# M55M1 register map
File version: 1.0
Registers are 32-bit, read-write, reset 0x0 unless marked. A register's access mark holds for its fields unless they carry their own. Offsets are from the block's base; [hi:lo] are bit positions; {n}, {i} and the like mark numbered series; 'fields as' and 'values as' point back to an identical list.

## SPIM0 — SPIM Register Map
Base 0x40042000
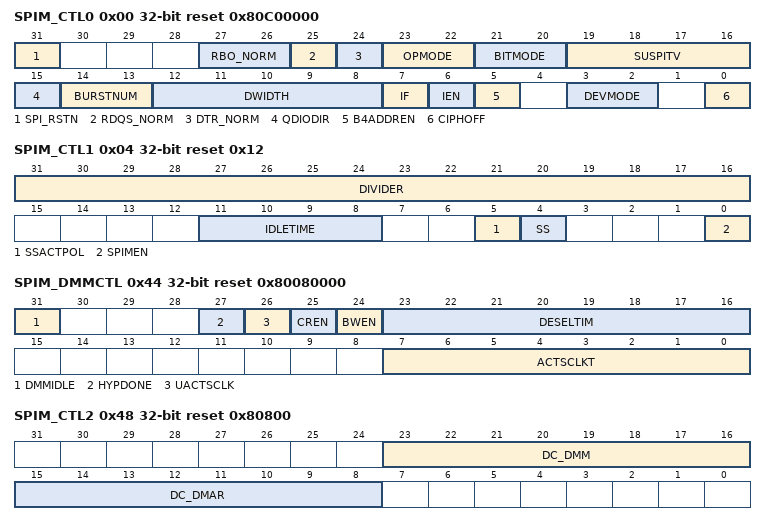
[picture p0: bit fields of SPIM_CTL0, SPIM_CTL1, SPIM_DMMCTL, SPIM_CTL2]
0x00 SPIM_CTL0 reset 0x80C00000 — Control and Status Register 0
  [31] SPI_RSTN — SPI Flash Reset Enable Bit for SPI Flash
    0=Set SPIM_RESETn pin to low; 1=Set SPIM_RESETn to high (Default)
  [27:26] RBO_NORM — Received Data Byte Order of Normal I/O Mode for Octal SPI Flash
    0=Byte order of received data from SPI Flash is byte0. Byte order of received data from SPI Flash is byte0, byte1. Byte order of received data from SPI Flash is byte0, byte1, byte2. Byte order of received data from SPI Flash is byte0, byte1, byte2, byte3; 1=Byte order of received data from SPI Flash is byte1, byte0. Byte order of received data from SPI Flash is byte2, byte1, byte0. Byte order of received data from SPI Flash is byte3, byte2, byte1, byte0; 2=Byte order of received data from SPI Flash is byte1, byte0, byte3, byte2; 3=Byte order of received data from SPI Flash is byte2, byte3, byte0, byte1
  [25] RDQS_NORM — Read DQS Mode Enable Bit for Normal I/O Mode. In SPI master mode, SPI uses read DQS signal, which is generated by SPI Flash, to sample RX data from SPI Flash when Read DQS mode is enabled. Note: Only used for normal I/O mode.
    0=Read DQS mode Disabled; 1=Read DQS mode Enabled
  [24] DTR_NORM — Double Transfer Rate Mode Enable Bit for Normal I/O Mode. In master mode, SPI will receive data at both rising edge and falling edge of SPI bus clock. Note: Only used for normal I/O mode.
    0=DTR mode Disabled (i.e. Single Transfer Rate (STR) mode enabled); 1=DTR mode Enabled
  [23:22] OPMODE — SPI Function Operation Mode. Note 1: In DMA write mode, hardware will send just one page program command per operation. Users must take care of cross-page cases. Note 2: For SPI Flash and Hyper device with 32 Mbytes, access address range is from 0x00000000 to 0x01FFFFFF when using Normal I/O mode, DMA write mode, and DMA read mode to write/read SPI Flash and Hyper device. Please user check size of used SPI Flash component to know access address range of SPI Flash and Hyper device. Note 3: For SPI Flash and Hyper device with 32 Mbytes, access address range is from 0x08000000 to 0x09FFFFFF when using Direct Memory mapping mode (DMM mode) to read SPI Flash and write/read Hyper device. Please user check size of used storage components to know access address range.
    0=Normal I/O mode; 1=DMA write mode; 2=DMA read mode; 3=Direct Memory Mapping mode (DMM mode) (Default)
  [21:20] BITMODE — SPI Interface Bit Mode. Note: Only used for normal I/O mode.
    0=Standard mode; 1=Dual mode; 2=Quad mode; 3=Octal mode
  [19:16] SUSPITV — Suspend Interval. Note: Only used for normal I/O mode.
    0=Hardware will control this item by DIVIDER (SPIM_CTL1[31:16]) automatically; 1=8 AHB clock cycles; 14=21 AHB clock cycles; 15=22 AHB clock cycles
  [15] QDIODIR — SPI Interface Direction Select for Normal I/O Mode. Note: Only used for normal I/O mode.
    0=Interface signals are input; 1=Interface signals are output
  [14:13] BURSTNUM — Transmit/Receive Burst Number. This field specifies how many transmit/receive transactions should be executed continuously in one transfer. Note: Only used for normal I/O Mode.
    0=Only one transmit/receive transaction will be executed in one transfer; 1=Two successive transmit/receive transactions will be executed in one transfer; 2=Three successive transmit/receive transactions will be executed in one transfer; 3=Four successive transmit/receive transactions will be executed in one transfer
  [12:8] DWIDTH — Transmit/Receive Bit Length. This specifies how many bits are transmitted/received in one transmit/receive transaction. Note 1: Only used for normal I/O mode. Note 2: Only 8, 16, 24, and 32 bits are allowed. Other bit length will result in incorrect transfer. Note 3: Only 16 and 32 bits are allowed when both of Octal mode and DTR mode of normal I/O mode are enabled. Other bit length will result in incorrect transfer.
    7=8 bits; 15=16 bits; 23=24 bits; 31=32 bits
  [7] IF — Interrupt Flag. Write Operation:
    0=No effect. The transfer has not finished yet; 1=Write 1 to clear. The transfer has done
  [6] IEN — Interrupt Enable Bit
    0=SPIM Interrupt Disabled; 1=SPIM Interrupt Enabled
  [5] B4ADDREN — 4-byte Address Mode Enable Bit. Note: Used for DMA write mode, DMA read mode, and DMM mode.
    0=3-byte address mode Enabled; 1=4-byte address mode Enabled
  [3:2] DEVMODE — Device Mode
    0=SPIROM operates in SPI Flash device mode; 1=SPIROM operates in HYPER RAM device mode; 2=SPIROM operates in HYPER Flash device mode
  [0] CIPHOFF — Cipher Disable Bit
    0=Cipher function Enabled; 1=Cipher function Disabled
0x04 SPIM_CTL1 reset 0x12 — Control and Status Register 1
  [31:16] DIVIDER — Clock Divider Register. The value in this field is the frequency divider of the AHB clock (HCLK) to generate the serial SPI output clock 'SCLK' on the output SPIM_CLK pin. The desired frequency is obtained according to the following equation: . Note 1: When set DIVIDER to zero, the frequency of SPIM_CLK will be equal to the frequency of HCLK. Note 2: SCLK is serial SPI output clock. Note 3: Each SPI Flash command has the limitation of the maximum operation frequency of SCLK. Please check the specification of the used SPI Flash component to decide the frequency of SPI Flash clock for different command operations of SPI Flash. Note 4: For DTR (Double Transfer Rate) commands, the setting values of DIVIDER are only 1,2,4,8,16,32,.... Note 5: For commands of HyperBus device, the setting values of DIVIDER are only 1 and 2.
  [11:8] IDLETIME — Idle Time Interval. In DMM mode, IDLETIME is set to control the minimum idle time between two SPI Flash accesses.
  [5] SSACTPOL — Slave Select Active Level. It defines the active level of device/slave select signal (SPIM_SS), as shown in Table 6.341
    0=The SPIM_SS slave select signal is active low; 1=The SPIM_SS slave select signal is active high
  [4] SS — Slave Select Active Enable Bit. Note: This interface can only drive one device/slave at a given time. Therefore, the slave selects of the selected device must be set to its active level before starting any read or write transfer. Functional description of SSACTPOL(SPIM_CTL1[5]) and SS is shown in Table 6.341
    0=SPIM_SS is in active level; 1=SPIM_SS is in inactive level (Default)
  [0] SPIMEN — Go and Busy Status. Write Operation: Note: All registers should be set before writing 1 to the SPIMEN bit. When a transfer is in progress, user should not write to any register of this peripheral.
    0=No effect. The transfer has done; 1=Start the transfer. This bit remains set during the transfer and is automatically cleared after transfer finished. The transfer has not finished yet
0x0C SPIM_RXCLKDLY — RX Clock Delay Control Register
  [3:0] RDDLYSEL — Sampling Clock Delay Selection for Received Data for Normal I/O Mode, DMA Read Mode, DMA Write Mode, Direct Memory Mapping Mode, and SPI FLASH Only. Determine the number of inserted delay cycles. Used to adjust the sampling clock of received data to latch the correct data. 0x0: No delay. (Default). 0x1: Delay 0.5 SPI Flash clock. 0x2: Delay 1 SPI Flash clocks. 0x3: Delay 1.5 SPI Flash clocks. ... 0xf: Delay 7.5 SPI Flash clocks. Note 1: The manufacturer or device ID of SPI Flash component can be used to determine the correct setting value of RDDLYSEL. An example is given as follows. For example, the manufacturer ID and device ID of SPI Flash for some vendor are 0xEF and 0x1234 separately. First, set RDDLYSEL to 0x0, and use read manufacturer id/device id command to read the manufacturer id of SPI Flash by using normal I/O mode (the manufacturer id is 0xEF (1110_1111) in this example). If the manufacturer ID which reads from SPI Flash is 0xF7 (1111_0111), it denotes that manufacturer id is shifted the right by 1 bit and most significant bit (MSB) of manufacturer id is assigned to 1. According to manufacturer id reads from SPI Flash, RDDLYSEL needs to be set to 0x1 to receive SPI Flash data correctly. Note 2: If read command of SPI FLASH sneds out DS (Data Strobe), and we recommand to use DS and HYPERDLL to sample RX data from SPI FLASH. RDDLYSEL is only used to sample RX data when read command of SPI FLASH doesn't send out DS (Data Strobe).
{0x10+4i} SPIM_RX{i} ro (i=0..3) — Data Receive Register {i}
  [31:0] RXDAT — Data Receive Register. The Data Receive Registers hold the received data of the last executed transfer. Number of valid RX registers is specified in SPIM_CTL0[BURSTNUM]. If BURSTNUM 0, received data are held in the most significant RXDAT register first. Number of valid-bit is specified in SPIM_CTL0[DWIDTH]. If DWIDTH is 16, 24, or 32, received data are held in the least significant byte of RXDAT register first. In a byte, received data are held in the most significant bit of RXDAT register first.
{0x20+4i} SPIM_TX{i} (i=0..3) — Data Transmit Register {i}
  [31:0] TXDAT — Data Transmit Register. The Data Transmit Registers hold the data to be transmitted in next transfer. Number of valid TXDAT registers is specified in SPIM_CTL0[BURSTNUM]. If BURSTNUM 0, data are transmitted in the most significant TXDAT register first. Number of valid-bit is specified in SPIM_CTL0[DWIDTH]. If DWIDTH is 16, 24, or 32, data are transmitted in the least significant byte of TXDAT register first. In a byte, data are transmitted in the most significant bit of TXDAT register first.
0x30 SPIM_SRAMADDR — SRAM Memory Address Register
  [31:0] ADDR — SRAM Memory Address. For DMA Read mode, this is the destination address for DMA transfer. For DMA Write mode, this is the source address for DMA transfer. Note: This address must be 8bytes aligned.
0x34 SPIM_DMACNT — DMA Transfer Byte Count Register
  [23:0] DMACNT — DMA Transfer Byte Count Register. It indicates the transfer length for DMA process. Note 1: The unit for counting is byte and the number must be the multiple of 8. Note 2: The page program instruction allows from one byte to 256 bytes (a page) of data to be programmed at previously erased (FFh) memory locations for SPI Flash device. Note 3: A maximum of 512 bytes can be programmed as long as an aligned 512-byte address boundary is not crossed for HYPER Flash device. Note 4: Please check specification of used SPI Flash and Hyper Flash to know maximum byte length of page program and program address boundary.
0x38 SPIM_FADDR — Address Register for SPI Flash and Hyper Device
  [31:0] ADDR — Address Register for SPI Flash and Hyper Device. For DMA Read mode, this is the source address for DMA transfer. For DMA Write mode, this is the destination address for DMA transfer. Note 1: This address must be 8bytes aligned. Note 2: A maximum of 512 bytes can be programmed as long as an aligned 512-byte address boundary is not crossed for HYPER Flash device. Note 3: For SPI Flash and Hyper device with 32 Mbytes, the value 'ADDR' is from 0x00000000 to 0x00FFFFFF when using DMA write mode and DMA read mode to write/read data of SPI Flash and Hyper device. Please check specification of used SPI Flash and Hyper Flash to know access address range and program address boundary.
0x44 SPIM_DMMCTL reset 0x80080000 — Direct Memory Mapping Mode Control Register
  [31] DMMIDLE — DMM Mode Idle State for DMM mode only. Note 1: User can polling this status register to know DMM mode is in idle state or busy state when user wants to change OPMODE (SPIM_CTL0[23:22]) from DMM mode to Normal I/O mode/DMA write mode/DMA read mode, SPIM cipher enable/disable switch (SPIM_CTL[0]). Note 2: This status register keep to 1 when SPIM is in Normal I/O mode, DMA write mode, and DMA read mode.
    0=DMM mode is in busy state; 1=DMM mode is in idle state
  [27] HYPDONE — Set All Read/Write Operations Done in Direct Memory Mapping Mode for HYPER Device. Note 1: User must set this bit to 1 after all read/write operations are done in DMM mode for HYPER device, and wait this bit to 0 to indicate that finish process of all read/write operations is done in DMM mode for HYPER device. Note 2: User must set this bit to 1 before user switches SPIM operation mode (SPIM_CTL0[23:22]) from DMM mode to Normal I/O mode, DMA write mode, or DMA read mode.
    0=Finish process of all read/write operations is done in DMM mode for HYPER device; 1=Finish process of all read/write operations is executed in DMM mode for HYPER device. This bit is cleared by hardware automatically
  [26] UACTSCLK — User Sets SPI Flash Active SCLK Time for Direct Memory Mapping Mode, DMA Write Mode, and DMA Read Mode Only. Note: When user wants to set ACTSCLKT(SPIM_DMMCTL[7:0]) manually, please set UACTSCLK to 1.
    0=According to DIVIDER(SPIM_CTL1[31:16]), ACTSCLKT(SPIM_DMMCTL[7:0]) is set by hardware automatically. (Default); 1=Set ACTSCLKT(SPIM_DMMCTL[7:0]) by user manually
  [25] CREN — Continuous Read Mode Enable Bit for Direct Memory Mapping Mode, Read Command Codes 0xBB, 0xEB, 0xE7, 0x0D, 0xBD, and 0xED Only. For read operations of SPI Flash, commands of fast read quad I/O (0xEB), word read quad I/O (0xE7), fast read dual I/O (0xBB), DTR fast read (0x0D), DTR fast read dual I/O (0xBD), and DTR fast read quad I/O (0xED) can further reduce cycles of command phase overhead through setting the 'continuous read mode' after address phase. Note: When user sets CREN to 1 to use continuous read mode, SPIM_MODE must be set by used SPI Flash specifications.
    0=Continuous Read Mode Disabled. (Default); 1=Continuous Read Mode Enabled
  [24] BWEN — 16 Bytes Burst Wrap Mode Enable Bit for Direct Memory Mapping Mode, and Read Command Code 0xEB, and 0xE7 Only
    0=Burst Wrap Mode Disabled. (Default); 1=Burst Wrap Mode Enabled
  [23:16] DESELTIM — SPI Flash Deselect Time for Direct Memory Mapping Mode Only. Set the minimum time width of SPI Flash deselect time (i.e. Minimum SPIM_SS deselect time), as shown in Figure 6.345. Note 3: Please check the used SPI Flash specification to know the setting value of this register, and different SPI Flash vendor may use different setting values.
  [7:0] ACTSCLKT — SPI Flash Active SCLK Time for Direct Memory Mapping Mode, DMA Write Mode, and DMA Read Mode Only. The bits set time interval between SPIM SS active edge and the position edge of the first serial SPI output clock, as shown in Figure 6.345. Note 2: SCLK is SPI output clock. Note 3: Please check the used SPI Flash specification to know the setting value of this register, and different SPI Flash vendor may use different setting values.
0x48 SPIM_CTL2 reset 0x80800 — Control and Status Register 2
  [23:16] DC_DMM — Dummy Cycle Number for Direct Memory Mapping Mode Only. Set number of dummy cycles for direct memory mapping mode only. Note 1: When there is not any dummy cycles in this used read command of SPI Flash, user must set DC_DMM to 0x0. Note 2: Number of dummy cycles depends on the frequency of SPI output clock, SPI Flash vendor, and read command types. Please check the used SPI Flash specification to know the setting value of this number of dummy cycles.
  [15:8] DC_DMAR — Dummy Cycle Number for DMA Read Mode Only. Set number of dummy cycles for DMA read mode only. Note 1: When there is not any dummy cycles in this used read command of SPI Flash, user must set DC_DMAR to 0x0. Note 2: Number of dummy cycles depends on the frequency of SPI output clock, SPI Flash vendor, and read command types. Please check the used SPI Flash specification to know the setting value of this number of dummy cycles.
0x4C SPIM_CMDCODE — Command Code Register
  [31:0] CMDCODE — SPI Flash Command Code. The SPI Flash command codes are separated in the following types. Page Program Command Code for DMA Write mode of SPIM. Read Command Code for DMA Read mode and DMM mode of SPIM. Note 1: Quad mode of SPI Flash must be enabled first by normal I/O mode before using quad page program/quad read commands. Note 2: Please check SPI Flash specifications for support command codes. Note 3: Please disable 'continuous read mode' and 'burst wrap mode' before DMA write mode of SPI Flash controller is used to program data of SPI Flash.
0x50 SPIM_MODE — Mode Data Register
  [31:0] MODEDATA — Mode Data Register. Set output data for mode phase. When user sets this mode data (Note1) and set CREN(SPIM_DMMCTL[25]) to enter continuous read mode, this will reduce the command phase by eight clocks and allows the read address to be immediately entered after SPIM_SS asserted to active. (Note1). Note 1: Please check the used SPI Flash specification to know the setting value of this mode bits data, and different SPI Flash vendor may use different setting values.
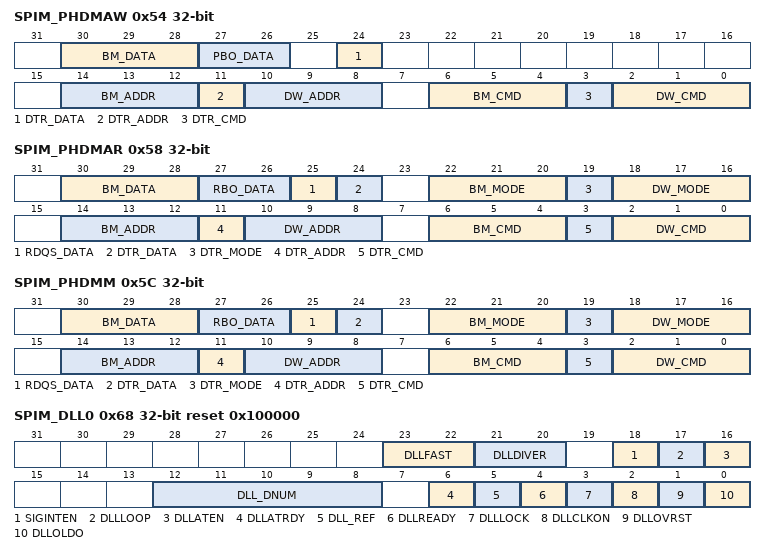
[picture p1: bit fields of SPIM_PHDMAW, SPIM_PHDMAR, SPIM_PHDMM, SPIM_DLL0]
0x54 SPIM_PHDMAW — Phase Setting Register for DMA Write Mode
  [30:28] BM_DATA — SPI Interface Bit Mode for Data Phase. Note: Only used for DMA Write mode.
    0=Standard mode; 1=Dual mode; 2=Quad mode; 3=Octal mode
  [27:26] PBO_DATA — Program Data Byte Order of Program Data Phase for Octal SPI Flash. Note: Only used for DMA Write mode.
    0=Byte order of program data to SPI Flash is byte0, byte1, byte2, byte3, byte4, byte5, byte6, byte7; 1=Byte order of program data to SPI Flash is byte7, byte6, byte5, byte4, byte3, byte2, byte1, byte0; 2=Byte order of program data to SPI Flash is byte1, byte0, byte3, byte2, byte5, byte4, byte7, byte6; 3=Byte order of program data to SPI Flash is byte6, byte7, byte4, byte5, byte2, byte3, byte0, byte1
  [24] DTR_DATA — Double Transfer Rate Mode Enable Bit for Data Phase. In master mode, SPI will receive data at both rising edge and falling edge of SPI bus clock. Note: Only used for DMA Write mode.
    values as SPIM_CTL0.DTR_NORM
  [14:12] BM_ADDR — SPI Interface Bit Mode for Address Phase. Note: Only used for DMA Write mode.
    0=Standard mode; 1=Dual mode; 2=Quad mode; 3=Octal mode
  [11] DTR_ADDR — Double Transfer Rate Mode Enable Bit for Address Phase. In master mode, SPI will transmit data at both rising edge and falling edge of SPI bus clock. Note: Only used for DMA Write mode.
    values as SPIM_CTL0.DTR_NORM
  [10:8] DW_ADDR — Data Width for Address Phase. This specifies how many bits are transmitted in this phase. Note: Only used for DMA Write mode.
    0=No address phase; 1=8 bits; 2=16 bits; 3=24 bits; 4=32 bits
  [6:4] BM_CMD — SPI Interface Bit Mode for Command Phase. Note: Only used for DMA Write mode.
    0=Standard mode; 1=Dual mode; 2=Quad mode; 3=Octal mode
  [3] DTR_CMD — Double Transfer Rate Mode Enable Bit for Command Phase. In master mode, SPI will transmit data at both rising edge and falling edge of SPI bus clock. Note: Only used for DMA Write mode.
    values as SPIM_CTL0.DTR_NORM
  [2:0] DW_CMD — Data Width for Command Phase. This specifies how many bits are transmitted in this phase. Note: Only used for DMA Write mode.
    0=No command phase; 1=8 bits; 2=16 bits; 3=24 bits; 4=32 bits
0x58 SPIM_PHDMAR — Phase Setting Register for DMA Read Mode
  [30:28] BM_DATA — SPI Interface Bit Mode for Data Phase. Note: Only used for DMA Read mode.
    0=Standard mode; 1=Dual mode; 2=Quad mode; 3=Octal mode
  [27:26] RBO_DATA — Received Data Byte Order of Received Data Phase for Octal SPI Flash. Note: Only used for DMA Read mode.
    0=Byte order of received data to SPI Flash is byte0, byte1, byte2, byte3, byte4, byte5, byte6, byte7; 1=Byte order of received data to SPI Flash is byte7, byte6, byte5, byte4, byte3, byte2, byte1, byte0; 2=Byte order of received data to SPI Flash is byte1, byte0, byte3, byte2, byte5, byte4, byte7, byte6; 3=Byte order of received data to SPI Flash is byte6, byte7, byte4, byte5, byte2, byte3, byte0, byte1
  [25] RDQS_DATA — Read DQS Mode Enable Bit for Data Phase. In SPI master mode, SPI uses read DQS signal, which is generated by SPI Flash, to sample RX data from SPI Flash when Read DQS mode is enabled. Note: Only used for DMA Read mode.
    0=Read DQS mode Disabled; 1=Read DQS mode Enabled
  [24] DTR_DATA — Double Transfer Rate Mode Enable Bit for Data Phase. In master mode, SPI will receive data at both rising edge and falling edge of SPI bus clock. Note: Only used for DMA Read mode.
    values as SPIM_CTL0.DTR_NORM
  [22:20] BM_MODE — SPI Interface Bit Mode for Mode Phase. Note: Only used for DMA Read mode.
    0=Standard mode; 1=Dual mode; 2=Quad mode; 3=Octal mode
  [19] DTR_MODE — Double Transfer Rate Mode Enable Bit for Mode Phase. In master mode, SPI will transmit data at both rising edge and falling edge of SPI bus clock. Note: Only used for DMA Read mode.
    values as SPIM_CTL0.DTR_NORM
  [18:16] DW_MODE — Data Width for Mode Phase. This specifies how many bits are transmitted in this phase. Note: Only used for DMA Read mode.
    0=No mode phase; 1=8 bits; 2=16 bits; 3=24 bits; 4=32 bits
  [14:12] BM_ADDR — SPI Interface Bit Mode for Address Phase. Note: Only used for DMA Read mode.
    0=Standard mode; 1=Dual mode; 2=Quad mode; 3=Octal mode
  [11] DTR_ADDR — Double Transfer Rate Mode Enable Bit for Address Phase. In master mode, SPI will transmit data at both rising edge and falling edge of SPI bus clock. Note: Only used for DMA Read mode.
    values as SPIM_CTL0.DTR_NORM
  [10:8] DW_ADDR — Data Width for Address Phase. This specifies how many bits are transmitted in this phase. Note: Only used for DMA Read mode.
    values as SPIM_PHDMAW.DW_ADDR
  [6:4] BM_CMD — SPI Interface Bit Mode for Command Phase. Note: Only used for DMA Read mode.
    0=Standard mode; 1=Dual mode; 2=Quad mode; 3=Octal mode
  [3] DTR_CMD — Double Transfer Rate Mode Enable Bit for Command Phase. In master mode, SPI will transmit data at both rising edge and falling edge of SPI bus clock. Note: Only used for DMA Read mode.
    values as SPIM_CTL0.DTR_NORM
  [2:0] DW_CMD — Data Width for Command Phase. This specifies how many bits are transmitted in this phase. Note: Only used for DMA Read mode.
    values as SPIM_PHDMAW.DW_CMD
0x5C SPIM_PHDMM — Phase Setting Register for Direct Memory Mapping Mode
  [30:28] BM_DATA — SPI Interface Bit Mode for Data Phase. Note: Only used for Direct Memory Mapping mode.
    0=Standard mode; 1=Dual mode; 2=Quad mode; 3=Octal mode
  [27:26] RBO_DATA — Received Data Byte Order of Received Data Phase for Octal SPI Flash. Note: Only used for Direct Memory Mapping mode.
    values as SPIM_PHDMAR.RBO_DATA
  [25] RDQS_DATA — Read DQS Mode Enable Bit for Data Phase. In SPI master mode, SPI uses read DQS signal, which is generated by SPI Flash, to sample RX data from SPI Flash when Read DQS mode is enabled. Note: Only used for Direct Memory Mapping mode.
    0=Read DQS mode Disabled; 1=Read DQS mode Enabled
  [24] DTR_DATA — Double Transfer Rate Mode Enable Bit for Data Phase. In master mode, SPI will receive data at both rising edge and falling edge of SPI bus clock. Note: Only used for Direct Memory Mapping mode.
    values as SPIM_CTL0.DTR_NORM
  [22:20] BM_MODE — SPI Interface Bit Mode for Mode Phase. Note: Only used for Direct Memory Mapping mode.
    0=Standard mode; 1=Dual mode; 2=Quad mode; 3=Octal mode
  [19] DTR_MODE — Double Transfer Rate Mode Enable Bit for Mode Phase. In master mode, SPI will transmit data at both rising edge and falling edge of SPI bus clock. Note: Only used for Direct Memory Mapping mode.
    values as SPIM_CTL0.DTR_NORM
  [18:16] DW_MODE — Data Width for Mode Phase. This specifies how many bits are transmitted in this phase. Note: Only used for Direct Memory Mapping mode.
    0=No mode phase; 1=8 bits; 2=16 bits; 3=24 bits; 4=32 bits
  [14:12] BM_ADDR — SPI Interface Bit Mode for Address Phase. Note: Only used for Direct Memory Mapping mode.
    0=Standard mode; 1=Dual mode; 2=Quad mode; 3=Octal mode
  [11] DTR_ADDR — Double Transfer Rate Mode Enable Bit for Address Phase. In master mode, SPI will transmit data at both rising edge and falling edge of SPI bus clock. Note: Only used for Direct Memory Mapping mode.
    values as SPIM_CTL0.DTR_NORM
  [10:8] DW_ADDR — Data Width for Address Phase. This specifies how many bits are transmitted in this phase. Note: Only used for Direct Memory Mapping mode.
    values as SPIM_PHDMAW.DW_ADDR
  [6:4] BM_CMD — SPI Interface Bit Mode for Command Phase. Note: Only used for Direct Memory Mapping mode.
    0=Standard mode; 1=Dual mode; 2=Quad mode; 3=Octal mode
  [3] DTR_CMD — Double Transfer Rate Mode Enable Bit for Command Phase. In master mode, SPI will transmit data at both rising edge and falling edge of SPI bus clock. Note: Only used for Direct Memory Mapping mode.
    values as SPIM_CTL0.DTR_NORM
  [2:0] DW_CMD — Data Width for Command Phase. This specifies how many bits are transmitted in this phase. Note: Only used for Direct Memory Mapping mode.
    values as SPIM_PHDMAW.DW_CMD
0x68 SPIM_DLL0 reset 0x100000 — HYPERDLL Control and Status Register 0
  [23:22] DLLFAST — Band Selection of HYPERDLL Reference Clock
    0=When frequency of HYPERDLL reference clock equals to 100 MHz; 1=When frequency of HYPERDLL reference clock is greater than 100 MHz
  [21:20] DLLDIVER — Divider Number Selection of HYPERDLL Internal Clock Divder
    0=Output frequency of HYPERDLL internal clock divdier equals to input frequency of HYPERDLL internal clock divdier; 1=Output frequency of HYPERDLL internal clock divdier is (input frequency of HYPERDLL internal clock divdier)/2; 2=Output frequency of HYPERDLL internal clock divdier is (input frequency of HYPERDLL internal clock divdier)/4; 3=Output frequency of HYPERDLL internal clock divdier is (input frequency of HYPERDLL internal clock divdier)/8
  [18] SIGINTEN — Selection for Clock Source DQS/RWDS of HYPERDLL Open Loop Delay Line
    0=HYPERDLL clock source DQS/RWDS of HYPERDLL open loop delay line is from SPI Flash and HYPER device; 1=HYPERDLL clock source DQS/RWDS of HYPERDLL open loop delay line is from HYPERDLL internal clock divider
  [17] DLLLOOP — HYPERDLL Delay Time Self-Test Enable Bit
    0=HYPERDLL Delay time self-test is disabled; 1=HYPERDLL Delay time self-test is enabled
  [16] DLLATEN — HYPERDLL Auto Trim Enable Bit
    0=HYPERDLL auto trim function is disabled for HYPERDLL normal mode and HYPERDLL BIST1 mode; 1=HYPERDLL auto trim function is enabled for HYPERDLL normal mode and HYPERDLL BIST1 mode
  [12:8] DLL_DNUM — HYPERDLL Delay Step Number. Set HYPERDLL delay step number. 0x0: No delay. (Default). 0x1: HYPERDLL delay read data strobe of RWDS and DQS with 1x (SPIM output bus clock period)/32. 0x2: HYPERDLL delay read data strobe of RWDS and DQS with 2x (SPIM output bus clock period)/32. 0x3: HYPERDLL delay read data strobe of RWDS and DQS with 3x (SPIM output bus clock period)/32 ... 0x1f: HYPERDLL delay read data strobe of RWDS and DQS with 31x (SPIM output bus clock period)/32
  [6] DLLATRDY ro — HYPERDLL Auto Trim Ready Status Bit (Read Only). Note 1: User needs to check status of HYPERDLL auto trim function before HYPERDLL output can be used for flow of HYPERDLL auto trim correctly. Note 2: This status bit is valid only when DLLATEN (SPIM_DLL0[16]) is enabled. Note 3: This status bit will be cleared to 0 when DLLATEN (SPIM_DLL0[16]) is disabled.
    0=HYPERDLL auto trim function is not in ready state when DLLATEN (SPIM_DLL0[16]) is enabled and HYPERDLL output is ready; 1=HYPERDLL auto trim function is in ready state when DLLATEN (SPIM_DLL0[16]) is enabled and HYPERDLL output is ready
  [5] DLL_REF ro — HYPERDLL Refresh Status Bit (Read Only). Note 1: This bit will be cleared automatically. Note 2: User needs to check this bit to know that the refresh flow of HYPERDLL circuit is finished or not.
    0=The updating flow of new HYPERDLL delay step number DLL_DNUM (SPIM_DLL0[13:8]) of HYPERDLL circuit is finished; 1=HYPERDLL circuit is updating the new HYPERDLL delay step number DLL_DNUM (SPIM_DLL0[13:8])
  [4] DLLREADY ro — HYPERDLL Output Ready Status Bit (Read Only). Note: User needs to check status of HYPERDLL output to ready before HYPERDLL output can be used correctly.
    0=HYPERDLL output is not ready, and HYPERDLL output is not ready to use; 1=HYPERDLL output is ready, and HYPERDLL output is ready to use
  [3] DLLLOCK ro — HYPERDLL Lock Status Bit (Read Only). Note: User needs to check HYPERDLL Datasheet to know HYPERDLL lock time.
    0=HYPERDLL is not locked after HYPERDLL reference clock sends to HYPERDLL circuit; 1=HYPERDLL is locked after HYPERDLL reference clock sends to HYPERDLL circuit
  [2] DLLCLKON ro — HYPERDLL Clock Divider Circuit Status Bit (Read Only). Note: User needs to check HYPERDLL Datasheet to know time interval that HYPERDLL clock divider circuit can be enabled after HYPERDLL OLDO is enabled.
    0=HYPERDLL clock divider circuit is disabled after HYPERDLL OLDO is enabled; 1=HYPERDLL clock divider circuit is enabled after HYPERDLL OLDO is enabled
  [1] DLLOVRST — HYPERDLL Output Valid Counter Reset Enable. Note 1: This bit will be cleared automatically. Note 2: User only writes 1'b1 to DLLOVRST once before user starts to trim delay step number of HYPERDLL. User needs to set DLLOVRST again to wait HYPERDLL output valid when one of frequencies of SPI output bus clock/HyperBus clock, HYPERDLL reference clock, or RWDS/DS clock are changed.
    0=HYPERDLL output valid counter is not reseted to 0x0 and it does not start to count; 1=HYPERDLL output valid counter is reseted to 0x0 and it starts to count from 0x0 to DLLOVNUM (SPIM_DLL1[15:0])
  [0] DLLOLDO — HYPERDLL OLDO Enable Bit. Note 1: HYPERDLL reference clock will start to send after user sets DLLOLDO to 0x1. Note 2: User only writes 1'b1 to DLLOLDO (SPIM_DLL0[0]) once before user starts to trim delay step number of HYPERDLL.
    0=HYPERDLL OLDO is disabled, and HYPERDLL circuit is in Power-down mode; 1=HYPERDLL OLDO is enabled, and HYPERDLL circuit is in power enable mode
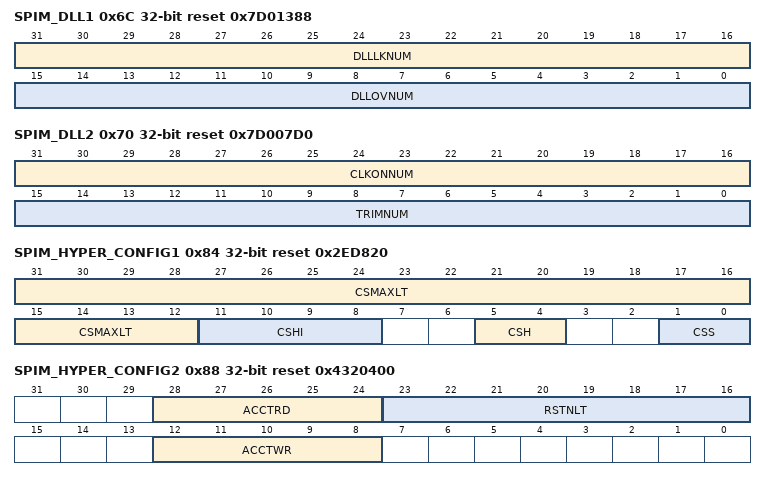
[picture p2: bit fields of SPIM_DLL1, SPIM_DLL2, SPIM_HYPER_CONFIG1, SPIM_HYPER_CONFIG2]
0x6C SPIM_DLL1 reset 0x7D01388 — HYPERDLL Control and Status Register 1
  [31:16] DLLLKNUM — Clock Cycle Number between HYPERDLL Clock Divider Enable and HYPERDLL Lock. Sets cycle number of HYPERDLL lock time after HYPERDLL clock divider is enabled. Note 1: User needs to check datasheet of HYPERDLL to know the time interval between HYPERDLL clock divider enable and HYPERDLL lock done. Note 2: The unit of this DLLLKNUM is cycle number of HYPERDLL reference clock that its frequency equals to frequency of SPIM output bus clock. Note 3: The default value is 0x07D0 when frequency of HYPERDLL reference clock is 100 MHz and HYPERDLL lock time is 20us.
  [15:0] DLLOVNUM — Clock Cycle Number between HYPERDLL Lock and HYPERDLL Output Valid. Set cycle number of HYPERDLL output valid. The hardware counter of HYPERDLL output valid will count from 0 to the DLLOVNUM after user sets DLLOVRST (SPIM_DLL0[1]) of HYPERDLL output valid counter to 0x1. Note 1: User needs to check datasheet of HYPERDLL to know the time interval between HYPERDLL lock done and HYPERDLL output valid. Note 2: The unit of this DLLOVNUM is cycle number of HYPERDLL reference clock that its frequency equals to frequency of SPIM output bus clock. Note 3: The default value is 0x1388 when frequency of HYPERDLL reference clock is 100 MHz and valid time of HYPERDLL output is 50us.
0x70 SPIM_DLL2 reset 0x7D007D0 — HYPERDLL Control and Status Register 2
  [31:16] CLKONNUM — Clock Cycle Number between HYPERDLL OLDO Enable and HYPERDLL Clock Divider Enable. Sets cycle number of HYPERDLL divider to be enabled after HYPERDLL OLDO is enabled. Note 1: User needs to check Datasheet of HYPERDLL to know the time interval between HYPERDLL OLDO enable and HYPERDLL clock divider enable. Note 2: The unit of this CLKONNUM is cycle number of HYPERDLL reference clock that its frequency equals to frequency of SPIM output bus clock. Note 3: The default value is 0x07D0 when frequency of HYPERDLL reference clock is 100 MHz and HYPERDLL lock time is 20us.
  [15:0] TRIMNUM — Clock Cycle Number between HYPERDLL Output Valid and HYPERDLL Auto Trim Enable. Sets cycle number of HYPERDLL auto trim to be enabled after HYPERDLL output is valid. Note 1: User needs to check Datasheet of HYPERDLL to know the time interval between HYPERDLL output valid and HYPERDLL auto trim enable. Note 2: The unit of this TRIMNUM is cycle number of HYPERDLL reference clock that its frequency equals to frequency of SPIM output bus clock. Note 3: The default value is 0x07D0 when frequency of HYPERDLL reference clock is 100 MHz and HYPERDLL lock time is 20us.
0x80 SPIM_HYPER_CMD — HyperBus Command and Status Register
  [3:0] HYPCMD — HyperBus Command and Status. Write. Note 1: When an operation is Done, the read value automatically return to 4'b0000. Note 2: The encryption and decryption of cipher are not supported, and it only uses to send command to HyperBus device, write control register to HyperBus device, and read status register from HyperBus device.
    0=HyperBus interface is Idle; 1=Reset Hyper RAM; 2=Read Hyper RAM regsiter (16-Bit, Read Data[15:0]; 5=Exit From Hybrid Sleep and deep power down; 7=Write Hyper RAM regsiter (16-Bit, Write Data[15:0]; 8=Read 2 Bytes (Read Data[15:0]) from memory space of HyperBus device; 9=Read 4 Bytes (Read Data[31:0]) from memory space of HyperBus device; 12=Write 1 Byte (Write Data[7:0]) to memory space of HyperBus device; 13=Write 2 Bytes (Write Data[15:0]) to memory space of HyperBus device; 14=Write 3 Bytes (Write Data[23:0]) to memory space of HyperBus device; 15=Write 4 Bytes (Write Data[31:0]) to memory space of HyperBus device
0x84 SPIM_HYPER_CONFIG1 reset 0x2ED820 — HyperBus Configuration Register 1
  [31:12] CSMAXLT — Chip Select Maximum Low Time. This field indicates the maximum Low period of the chip select (CS#) in one transaction . Note1 : This field inidcates the timing of Hyper RAM Chip Select specification so that it has to relative the frequency of HCLK and the DIVIDER (SPIM_CTL1[31:16]) and the unit of the above two formulas are clock cycle number of SPIM HCLK. Note2 : This register must be set to 0x000FFFFF for Hyper Flash device. Note3 : User needs to check specification of used HYPER RAM device to know the value of timing parameter tCSM with unit 'nano second' (ns).
    0=1 HCLK cycle; 1=2 HCLK cycles; 2=3 HCLK cycles; 3=4 HCLK cycles; 0x2ED=750 HCLK cycles (3750ns @200 MHz); 0xFFFFE=1048575 HCLK cycles; 0xFFFFF=1048576 HCLK cycles
  [11:8] CSHI — Chip Select High between Transaction. This field indicates the inactive period between two HyperBus transactions. Note: This field must meet the HyperBus device's specification of tCSHI.
    3=4 HCLK cycles; 15=16 HCLK cycles
  [5:4] CSH — Chip Select Hold Time After CK Falling Edge. This field indicates the hold time between the last CK falling edge and chip select. Note: Please set this register to 2'b11 when user uses control register SPIM_HYPER_CMD to read register/memory data from Hyper device.
    2=2.5 HCLK cycles; 3=3.5 HCLK cycles
  [1:0] CSS — Chip Select Setup Time to Next CK Rising Edge. This field indicates the setup time between the chip select and the next CK rising edge
    0=3.5 HCLK cycles. (default); 1=4.5 HCLK cycles
0x88 SPIM_HYPER_CONFIG2 reset 0x4320400 — HyperBus Configuration Register 2
  [28:24] ACCTRD — Initial Access Time for Read Data from HYPER Device. This field indicates the initial access cycles for read transaction of the HyperBus. Note1 : This field must be set to the same value as 'Initial Latency' for read operations in Configuration Register 0 in HYPER device. Note2 : If user sets value to 0000, the hardware will modify it to 0001 automatically.
    1=1 CK cycles; 2=2 CK cycles; 3=3 CK cycles; 4=4 CK cycles. (default); 5=5 CK cycles; 6=6 CK cycles; 7=7 CK cycles; 31=31 CK cycles
  [23:16] RSTNLT — HyperBus Device RESETN Low Time. This field indicates the low period of HyperBus device RESETN (RESET#). Note: This field inidcates the timing of HyperBus device RESET# specification so that it has to relative the frequency of HCLK.
    1=2 HCLK cycles; 2=3 HCLK cycles; 3=4 HCLK cycles; 255=255 HCLK cycles
  [12:8] ACCTWR — Initial Access Time for Write Data to HYPER Device. This field indicates the initial access cycles for write transaction of the HyperBus. Note1 : This field must be set to the same value as 'Initial Latency' for write operations in Configuration Register 0 in HYPER device. Note2 : If user sets value to 0000, the hardware will modify it to 0001 automatically.
    1=1 CK cycles; 2=2 CK cycles; 3=3 CK cycles; 4=4 CK cycles (default); 5=5 CK cycles; 6=6 CK cycles; 7=7 CK cycles; 31=31 CK cycles
0x8C SPIM_HYPER_ADR — HyperBus Address Register
  [24:0] HBADDR — HyperBus Register Address. Memory Space Range: 0x0000_0000 ~ 0x01FF_FFFF. Register Space Range: Note 1: It is 'Byte' address. Note 2: Up to 32 Mbytesytes of memory space is supported.
0x90 SPIM_HYPER_WDATA — HyperBus 32-Bits Write Data Register
  [31:0] HBWDATA — HyperBus 32-Bits Write Data. To write 1 Byte to HyperBus device, Byte 0 (Data[7:0]) is used. To write 2 Bytes to HyperBus device, Byte 1~0 (Data[15:0]) is used. To write 3 Bytes to HyperBus device, Byte 2~0 (Data[23:0]) is used. To write 4 Bytes to HyperBus device, Byte 3~0 (Data[31:0]) is used
0x94 SPIM_HYPER_RDATA ro — HyperBus 32-Bits Read Data Register
  [31:0] HBRDATA — HyperBus 32-bits Read Data. 32-Bits data read from HyperBus device. Note 1: The byte order of read data is little endian only.
0x98 SPIM_HYPER_INTEN — HyperBus Interrupt Enable Register
  [0] OPINTEN — HyperBus Operation Done Interrupt Enable
    0=Operation done interrupt is Disabled; 1=Operation done interrupt is Enabled
0x9C SPIM_HYPER_INTSTS — HyperBus Interrupt Status Register
  [0] OPDONE — HyperBus Operation Done Interrupt
    0=HyperBus operation is busy; 1=HyperBus operation is done
0xA0 SPIM_DMM_TIMEOUT_INTERVAL reset 0xFFFF
  [31:0] TOCNTDMM — Time-Out Counter Setting Value for DMM Read Mode only. User can set this control register to know if SPIM DMM mode doesn't response read data to MCU over the time interval by this time-out counter settings value, and the time-out event flag of DMM mode (SPIM_DMM_TIMEOUT_FLAG_STS[0]) will go high. Note 1: The time interval by this time-out counter settings value equals to time-out counter settings value multiple by clock cycle period of SPIM HCLK. Note 2: If setting value of this control register is smaller than 0x1000, then hardware will set this control register to 0x1000 automatically.
0xA4 SPIM_DMM_TIMEOUT_FLAG_STS — SPIM DMM Time-out Flag Status Register
  [0] DMMTOF — Time-out Flag for DMM Read Mode only. Note: Write 1 to clear to 0 for this time-out event flag of DMM mode.
    0=There is no time-out event when SPIM is in DMM read mode; 1=There is time-out event when SPIM is in DMM read mode
